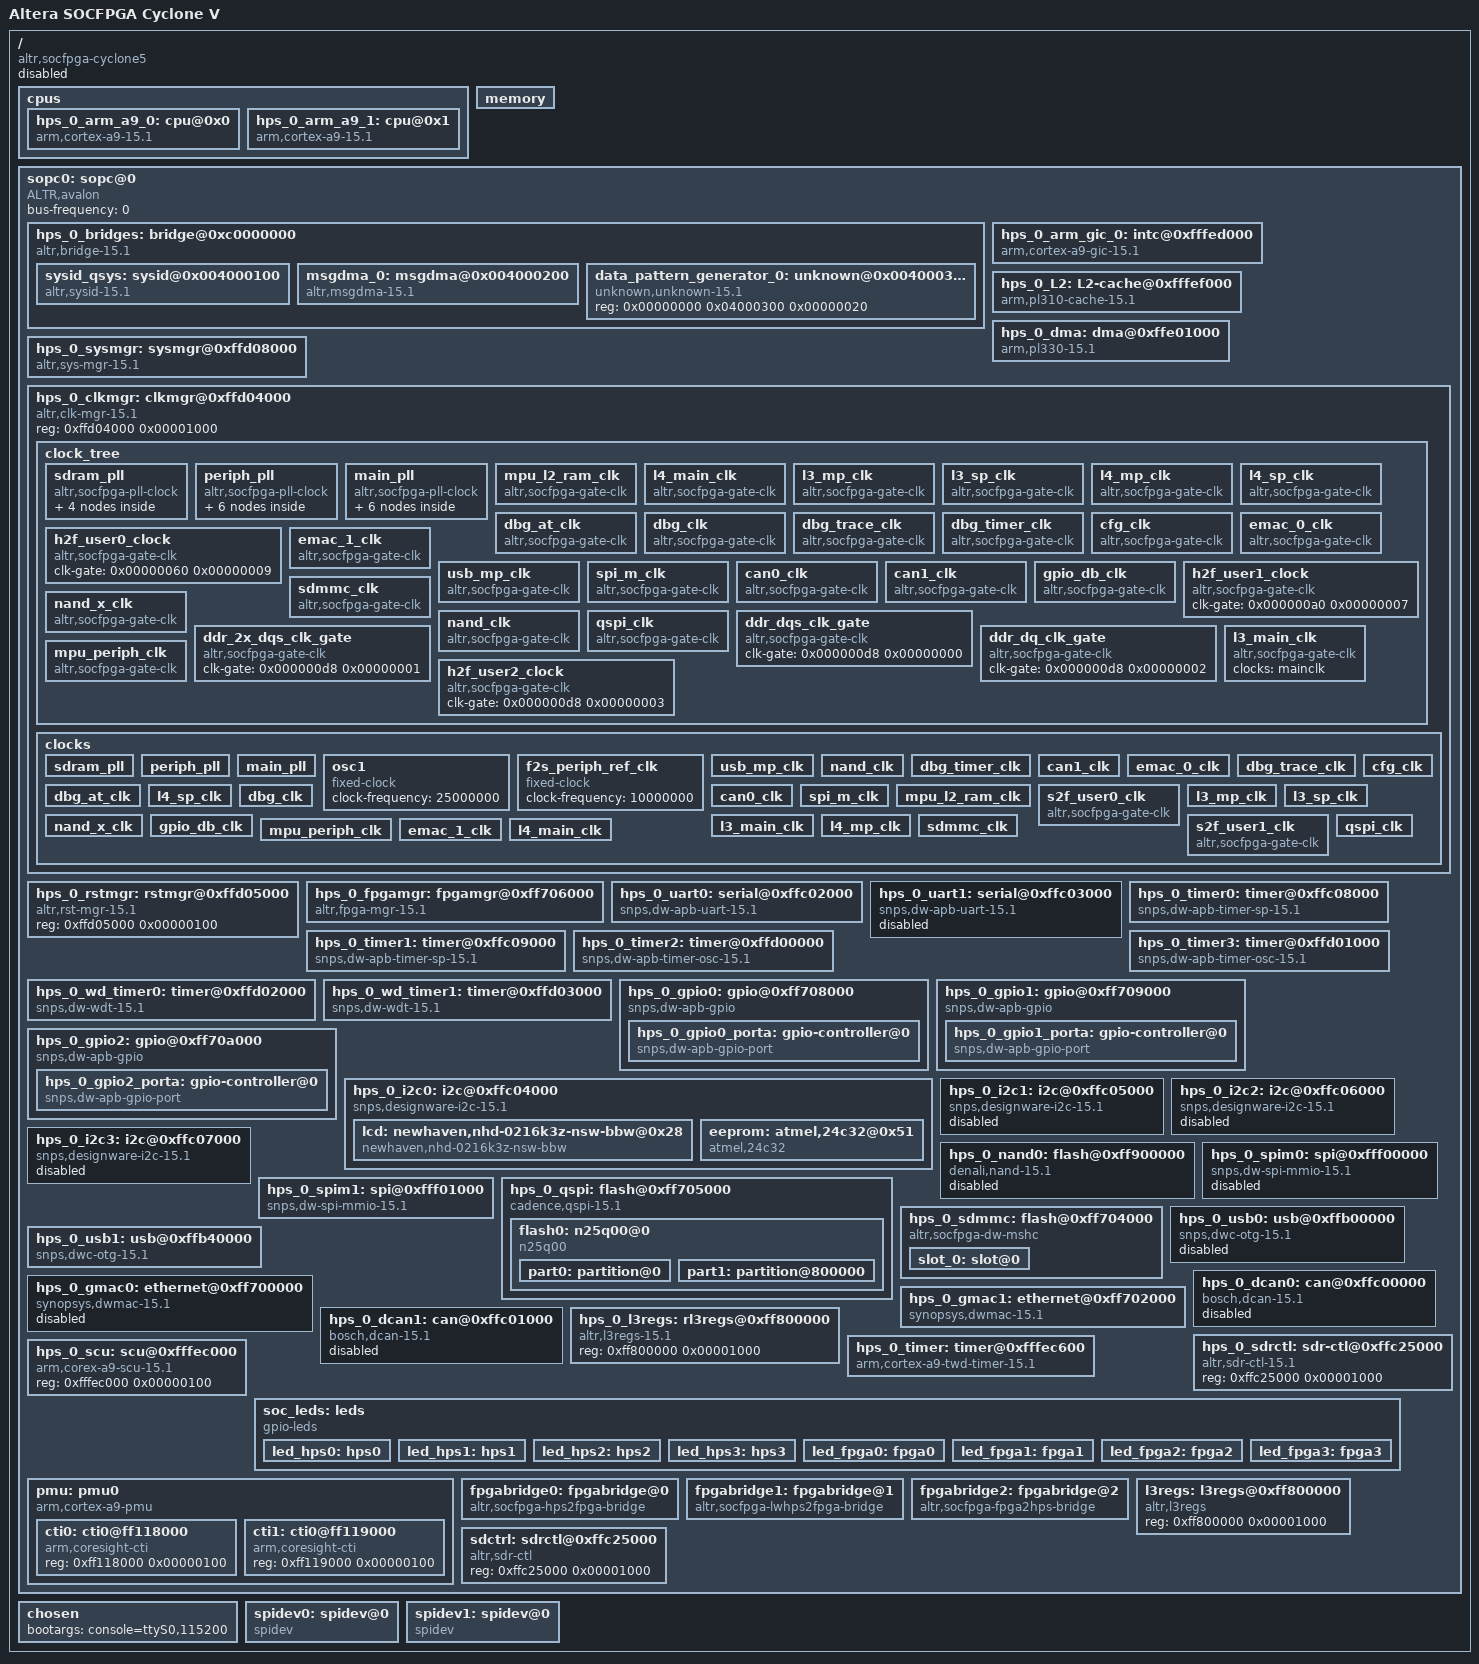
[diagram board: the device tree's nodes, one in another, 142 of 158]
/*
 * This devicetree is generated by sopc2dts version 15.1 [94267f754b718da09506aebbe5343be8fdba1582] on Mon Jul 25 16:30:17 CST 2016
 * Sopc2dts is written by Walter Goossens <waltergoossens@home.nl>
 * in cooperation with the nios2 community <nios2-dev@lists.rocketboards.org>
 */
/dts-v1/;

/ {
	model = "Altera SOCFPGA Cyclone V";	/* appended from boardinfo */
	compatible = "altr,socfpga-cyclone5", "altr,socfpga";	/* appended from boardinfo */
	#address-cells = <1>;
	#size-cells = <1>;
	status = "disabled";	/* appended from boardinfo */
	clocks = <&per_base_clk>;	/* appended from boardinfo */

	cpus {
		#address-cells = <1>;
		#size-cells = <0>;

		hps_0_arm_a9_0: cpu@0x0 {
			device_type = "cpu";
			compatible = "arm,cortex-a9-15.1", "arm,cortex-a9";
			reg = <0x00000000>;
			next-level-cache = <&hps_0_L2>;	/* appended from boardinfo */
		}; //end cpu@0x0 (hps_0_arm_a9_0)

		hps_0_arm_a9_1: cpu@0x1 {
			device_type = "cpu";
			compatible = "arm,cortex-a9-15.1", "arm,cortex-a9";
			reg = <0x00000001>;
			next-level-cache = <&hps_0_L2>;	/* appended from boardinfo */
		}; //end cpu@0x1 (hps_0_arm_a9_1)
	}; //end cpus

	memory {
		device_type = "memory";
		reg = <0xc0000000 0x04000000>,
			<0xffff0000 0x00010000>,
			<0x00000000 0x80000000>;
	}; //end memory

	sopc0: sopc@0 {
		device_type = "soc";
		ranges;
		#address-cells = <1>;
		#size-cells = <1>;
		compatible = "ALTR,avalon", "simple-bus";
		bus-frequency = <0>;

		hps_0_bridges: bridge@0xc0000000 {
			compatible = "altr,bridge-15.1", "simple-bus";
			reg = <0xc0000000 0x20000000>,
				<0xff200000 0x00200000>;
			reg-names = "axi_h2f", "axi_h2f_lw";
			#address-cells = <2>;
			#size-cells = <1>;
			ranges = <0x00000000 0x04000100 0xc4000100 0x00000008>,
				<0x00000000 0x04000200 0xc4000200 0x00000020>,
				<0x00000000 0x04000300 0xc4000300 0x00000020>,
				<0x00000000 0x04000240 0xc4000240 0x00000010>,
				<0x00000000 0x00000000 0xc0000000 0x04000000>;

			sysid_qsys: sysid@0x004000100 {
				compatible = "altr,sysid-15.1", "altr,sysid-1.0";
				reg = <0x00000000 0x04000100 0x00000008>;
				id = <2899645186>;	/* embeddedsw.dts.params.id type NUMBER */
				timestamp = <1469198027>;	/* embeddedsw.dts.params.timestamp type NUMBER */
			}; //end sysid@0x004000100 (sysid_qsys)

			msgdma_0: msgdma@0x004000200 {
				compatible = "altr,msgdma-15.1", "altr,msgdma-1.0";
				reg = <0x00000000 0x04000200 0x00000020>,
					<0x00000000 0x04000240 0x00000010>;
				reg-names = "csr", "descriptor_slave";
			}; //end msgdma@0x004000200 (msgdma_0)

			data_pattern_generator_0: unknown@0x004000300 {
				compatible = "unknown,unknown-15.1";
				reg = <0x00000000 0x04000300 0x00000020>;
			}; //end unknown@0x004000300 (data_pattern_generator_0)
		}; //end bridge@0xc0000000 (hps_0_bridges)

		hps_0_arm_gic_0: intc@0xfffed000 {
			compatible = "arm,cortex-a9-gic-15.1", "arm,cortex-a9-gic";
			reg = <0xfffed000 0x00001000>,
				<0xfffec100 0x00000100>;
			reg-names = "axi_slave0", "axi_slave1";
			interrupt-controller;
			#interrupt-cells = <3>;
		}; //end intc@0xfffed000 (hps_0_arm_gic_0)

		hps_0_L2: L2-cache@0xfffef000 {
			compatible = "arm,pl310-cache-15.1", "arm,pl310-cache";
			reg = <0xfffef000 0x00001000>;
			interrupt-parent = <&hps_0_arm_gic_0>;
			interrupts = <0 38 4>;
			cache-level = <2>;	/* embeddedsw.dts.params.cache-level type NUMBER */
			cache-unified;	/* appended from boardinfo */
			arm,tag-latency = <1 1 1>;	/* appended from boardinfo */
			arm,data-latency = <2 1 1>;	/* appended from boardinfo */
		}; //end L2-cache@0xfffef000 (hps_0_L2)

		hps_0_dma: dma@0xffe01000 {
			compatible = "arm,pl330-15.1", "arm,pl330", "arm,primecell";
			reg = <0xffe01000 0x00001000>;
			interrupt-parent = <&hps_0_arm_gic_0>;
			interrupts = <0 104 4>;
			#dma-cells = <1>;	/* embeddedsw.dts.params.#dma-cells type NUMBER */
			#dma-channels = <8>;	/* embeddedsw.dts.params.#dma-channels type NUMBER */
			#dma-requests = <32>;	/* embeddedsw.dts.params.#dma-requests type NUMBER */
			clock-names = "apb_pclk";	/* embeddedsw.dts.params.clock-names type STRING */
			copy-align = <3>;	/* embeddedsw.dts.params.copy-align type NUMBER */
			nr-irqs = <9>;	/* embeddedsw.dts.params.nr-irqs type NUMBER */
			nr-valid-peri = <9>;	/* embeddedsw.dts.params.nr-valid-peri type NUMBER */
		}; //end dma@0xffe01000 (hps_0_dma)

		hps_0_sysmgr: sysmgr@0xffd08000 {
			compatible = "altr,sys-mgr-15.1", "altr,sys-mgr", "syscon", "syscon";
			reg = <0xffd08000 0x00000400>;
			cpu1-start-addr = <0xffd080c4>;	/* appended from boardinfo */
		}; //end sysmgr@0xffd08000 (hps_0_sysmgr)

		hps_0_clkmgr: clkmgr@0xffd04000 {
			compatible = "altr,clk-mgr-15.1", "altr,clk-mgr";
			reg = <0xffd04000 0x00001000>;

			clock_tree {
				#size-cells = <0>;
				#address-cells = <1>;

				sdram_pll: sdram_pll {
					compatible = "altr,socfpga-pll-clock";	/* appended from boardinfo */
					reg = <0x000000c0>;	/* appended from boardinfo */
					#clock-cells = <0>;	/* appended from boardinfo */
					#address-cells = <1>;	/* appended from boardinfo */
					#size-cells = <0>;	/* appended from boardinfo */
					clocks = <&osc1>;	/* appended from boardinfo */

					ddr_dqs_clk: ddr_dqs_clk {
						compatible = "altr,socfpga-perip-clk";	/* appended from boardinfo */
						reg = <0x000000c8>;	/* appended from boardinfo */
						#clock-cells = <0>;	/* appended from boardinfo */
						clocks = <&sdram_pll>;	/* appended from boardinfo */
					}; //end ddr_dqs_clk (ddr_dqs_clk)

					ddr_2x_dqs_clk: ddr_2x_dqs_clk {
						compatible = "altr,socfpga-perip-clk";	/* appended from boardinfo */
						reg = <0x000000cc>;	/* appended from boardinfo */
						#clock-cells = <0>;	/* appended from boardinfo */
						clocks = <&sdram_pll>;	/* appended from boardinfo */
					}; //end ddr_2x_dqs_clk (ddr_2x_dqs_clk)

					ddr_dq_clk: ddr_dq_clk {
						compatible = "altr,socfpga-perip-clk";	/* appended from boardinfo */
						reg = <0x000000d0>;	/* appended from boardinfo */
						#clock-cells = <0>;	/* appended from boardinfo */
						clocks = <&sdram_pll>;	/* appended from boardinfo */
					}; //end ddr_dq_clk (ddr_dq_clk)

					s2f_usr2_clk: s2f_usr2_clk {
						compatible = "altr,socfpga-perip-clk";	/* appended from boardinfo */
						reg = <0x000000d4>;	/* appended from boardinfo */
						#clock-cells = <0>;	/* appended from boardinfo */
						clocks = <&sdram_pll>;	/* appended from boardinfo */
					}; //end s2f_usr2_clk (s2f_usr2_clk)

					ddr_dqs_clk: ddr_dqs_clk {
					}; //end ddr_dqs_clk (ddr_dqs_clk)

					ddr_2x_dqs_clk: ddr_2x_dqs_clk {
					}; //end ddr_2x_dqs_clk (ddr_2x_dqs_clk)

					ddr_dq_clk: ddr_dq_clk {
					}; //end ddr_dq_clk (ddr_dq_clk)

					s2f_usr2_clk: s2f_usr2_clk {
					}; //end s2f_usr2_clk (s2f_usr2_clk)
				}; //end sdram_pll (sdram_pll)

				periph_pll: periph_pll {
					compatible = "altr,socfpga-pll-clock";	/* appended from boardinfo */
					reg = <0x00000080>;	/* appended from boardinfo */
					#clock-cells = <0>;	/* appended from boardinfo */
					#address-cells = <1>;	/* appended from boardinfo */
					#size-cells = <0>;	/* appended from boardinfo */
					clocks = <&osc1>;	/* appended from boardinfo */

					per_nand_mmc_clk: per_nand_mmc_clk {
						compatible = "altr,socfpga-perip-clk";	/* appended from boardinfo */
						reg = <0x00000094>;	/* appended from boardinfo */
						#clock-cells = <0>;	/* appended from boardinfo */
						clocks = <&periph_pll>;	/* appended from boardinfo */
					}; //end per_nand_mmc_clk (per_nand_mmc_clk)

					per_base_clk: per_base_clk {
						compatible = "altr,socfpga-perip-clk";	/* appended from boardinfo */
						reg = <0x00000098>;	/* appended from boardinfo */
						#clock-cells = <0>;	/* appended from boardinfo */
						clocks = <&periph_pll>;	/* appended from boardinfo */
					}; //end per_base_clk (per_base_clk)

					per_qspi_clk: per_qspi_clk {
						compatible = "altr,socfpga-perip-clk";	/* appended from boardinfo */
						reg = <0x00000090>;	/* appended from boardinfo */
						#clock-cells = <0>;	/* appended from boardinfo */
						clocks = <&periph_pll>;	/* appended from boardinfo */
					}; //end per_qspi_clk (per_qspi_clk)

					s2f_usr1_clk: s2f_usr1_clk {
						compatible = "altr,socfpga-perip-clk";	/* appended from boardinfo */
						reg = <0x0000009c>;	/* appended from boardinfo */
						#clock-cells = <0>;	/* appended from boardinfo */
						clocks = <&periph_pll>;	/* appended from boardinfo */
					}; //end s2f_usr1_clk (s2f_usr1_clk)

					emac0_clk: emac0_clk {
						compatible = "altr,socfpga-perip-clk";	/* appended from boardinfo */
						reg = <0x00000088>;	/* appended from boardinfo */
						#clock-cells = <0>;	/* appended from boardinfo */
						clocks = <&periph_pll>;	/* appended from boardinfo */
					}; //end emac0_clk (emac0_clk)

					emac1_clk: emac1_clk {
						compatible = "altr,socfpga-perip-clk";	/* appended from boardinfo */
						reg = <0x0000008c>;	/* appended from boardinfo */
						#clock-cells = <0>;	/* appended from boardinfo */
						clocks = <&periph_pll>;	/* appended from boardinfo */
					}; //end emac1_clk (emac1_clk)

					per_nand_mmc_clk: per_nand_mmc_clk {
					}; //end per_nand_mmc_clk (per_nand_mmc_clk)

					per_base_clk: per_base_clk {
					}; //end per_base_clk (per_base_clk)

					per_qspi_clk: per_qspi_clk {
					}; //end per_qspi_clk (per_qspi_clk)

					s2f_usr1_clk: s2f_usr1_clk {
					}; //end s2f_usr1_clk (s2f_usr1_clk)

					emac0_clk: emac0_clk {
					}; //end emac0_clk (emac0_clk)

					emac1_clk: emac1_clk {
					}; //end emac1_clk (emac1_clk)
				}; //end periph_pll (periph_pll)

				main_pll: main_pll {
					compatible = "altr,socfpga-pll-clock";	/* appended from boardinfo */
					reg = <0x00000040>;	/* appended from boardinfo */
					#clock-cells = <0>;	/* appended from boardinfo */
					#address-cells = <1>;	/* appended from boardinfo */
					#size-cells = <0>;	/* appended from boardinfo */
					clocks = <&osc1>;	/* appended from boardinfo */

					cfg_s2f_usr0_clk: cfg_s2f_usr0_clk {
						compatible = "altr,socfpga-perip-clk";	/* appended from boardinfo */
						reg = <0x0000005c>;	/* appended from boardinfo */
						#clock-cells = <0>;	/* appended from boardinfo */
						clocks = <&main_pll>;	/* appended from boardinfo */
					}; //end cfg_s2f_usr0_clk (cfg_s2f_usr0_clk)

					main_qspi_clk: main_qspi_clk {
						compatible = "altr,socfpga-perip-clk";	/* appended from boardinfo */
						reg = <0x00000054>;	/* appended from boardinfo */
						#clock-cells = <0>;	/* appended from boardinfo */
						clocks = <&main_pll>;	/* appended from boardinfo */
					}; //end main_qspi_clk (main_qspi_clk)

					dbg_base_clk: dbg_base_clk {
						compatible = "altr,socfpga-perip-clk";	/* appended from boardinfo */
						reg = <0x00000050>;	/* appended from boardinfo */
						#clock-cells = <0>;	/* appended from boardinfo */
						div-reg = <0x000000e8 0x00000000 0x00000009>;
						clocks = <&main_pll>;	/* appended from boardinfo */
						fixed-divider = <4>;	/* appended from boardinfo */
					}; //end dbg_base_clk (dbg_base_clk)

					mpuclk: mpuclk {
						compatible = "altr,socfpga-perip-clk";	/* appended from boardinfo */
						reg = <0x00000048>;	/* appended from boardinfo */
						#clock-cells = <0>;	/* appended from boardinfo */
						div-reg = <0x000000e0 0x00000000 0x00000009>;
						clocks = <&main_pll>;	/* appended from boardinfo */
						fixed-divider = <2>;	/* appended from boardinfo */
					}; //end mpuclk (mpuclk)

					mainclk: mainclk {
						compatible = "altr,socfpga-perip-clk";	/* appended from boardinfo */
						reg = <0x0000004c>;	/* appended from boardinfo */
						#clock-cells = <0>;	/* appended from boardinfo */
						div-reg = <0x000000e4 0x00000000 0x00000009>;
						clocks = <&main_pll>;	/* appended from boardinfo */
						fixed-divider = <4>;	/* appended from boardinfo */
					}; //end mainclk (mainclk)

					main_nand_sdmmc_clk: main_nand_sdmmc_clk {
						compatible = "altr,socfpga-perip-clk";	/* appended from boardinfo */
						reg = <0x00000058>;	/* appended from boardinfo */
						#clock-cells = <0>;	/* appended from boardinfo */
						clocks = <&main_pll>;	/* appended from boardinfo */
					}; //end main_nand_sdmmc_clk (main_nand_sdmmc_clk)

					cfg_s2f_usr0_clk: cfg_s2f_usr0_clk {
					}; //end cfg_s2f_usr0_clk (cfg_s2f_usr0_clk)

					main_qspi_clk: main_qspi_clk {
					}; //end main_qspi_clk (main_qspi_clk)

					dbg_base_clk: dbg_base_clk {
					}; //end dbg_base_clk (dbg_base_clk)

					mpuclk: mpuclk {
					}; //end mpuclk (mpuclk)

					mainclk: mainclk {
					}; //end mainclk (mainclk)

					main_nand_sdmmc_clk: main_nand_sdmmc_clk {
					}; //end main_nand_sdmmc_clk (main_nand_sdmmc_clk)
				}; //end main_pll (main_pll)

				mpu_l2_ram_clk: mpu_l2_ram_clk {
					compatible = "altr,socfpga-gate-clk";	/* appended from boardinfo */
					#clock-cells = <0>;	/* appended from boardinfo */
					fixed-divider = <2>;	/* appended from boardinfo */
					clocks = <&mpuclk>;	/* appended from boardinfo */
				}; //end mpu_l2_ram_clk (mpu_l2_ram_clk)

				l4_main_clk: l4_main_clk {
					compatible = "altr,socfpga-gate-clk";	/* appended from boardinfo */
					#clock-cells = <0>;	/* appended from boardinfo */
					clk-gate = <0x00000060 0>;	/* appended from boardinfo */
					clocks = <&mainclk>;	/* appended from boardinfo */
				}; //end l4_main_clk (l4_main_clk)

				l3_mp_clk: l3_mp_clk {
					compatible = "altr,socfpga-gate-clk";	/* appended from boardinfo */
					#clock-cells = <0>;	/* appended from boardinfo */
					clk-gate = <0x00000060 1>;	/* appended from boardinfo */
					div-reg = <0x00000064 0 2>;	/* appended from boardinfo */
					clocks = <&mainclk>;	/* appended from boardinfo */
				}; //end l3_mp_clk (l3_mp_clk)

				l3_sp_clk: l3_sp_clk {
					compatible = "altr,socfpga-gate-clk";	/* appended from boardinfo */
					#clock-cells = <0>;	/* appended from boardinfo */
					div-reg = <0x00000064 2 2>;	/* appended from boardinfo */
					clocks = <&mainclk>;	/* appended from boardinfo */
				}; //end l3_sp_clk (l3_sp_clk)

				l4_mp_clk: l4_mp_clk {
					compatible = "altr,socfpga-gate-clk";	/* appended from boardinfo */
					#clock-cells = <0>;	/* appended from boardinfo */
					clk-gate = <0x00000060 2>;	/* appended from boardinfo */
					div-reg = <0x00000064 4 3>;	/* appended from boardinfo */
					clocks = <&mainclk>;	/* appended from boardinfo */
				}; //end l4_mp_clk (l4_mp_clk)

				l4_sp_clk: l4_sp_clk {
					compatible = "altr,socfpga-gate-clk";	/* appended from boardinfo */
					#clock-cells = <0>;	/* appended from boardinfo */
					clk-gate = <0x00000060 3>;	/* appended from boardinfo */
					div-reg = <0x00000064 7 3>;	/* appended from boardinfo */
					clocks = <&mainclk &per_base_clk>;	/* appended from boardinfo */
				}; //end l4_sp_clk (l4_sp_clk)

				dbg_at_clk: dbg_at_clk {
					compatible = "altr,socfpga-gate-clk";	/* appended from boardinfo */
					#clock-cells = <0>;	/* appended from boardinfo */
					clk-gate = <0x00000060 4>;	/* appended from boardinfo */
					div-reg = <0x00000068 0 2>;	/* appended from boardinfo */
					clocks = <&dbg_base_clk>;	/* appended from boardinfo */
				}; //end dbg_at_clk (dbg_at_clk)

				dbg_clk: dbg_clk {
					compatible = "altr,socfpga-gate-clk";	/* appended from boardinfo */
					#clock-cells = <0>;	/* appended from boardinfo */
					clk-gate = <0x00000060 5>;	/* appended from boardinfo */
					div-reg = <0x00000068 2 2>;	/* appended from boardinfo */
					clocks = <&dbg_base_clk>;	/* appended from boardinfo */
				}; //end dbg_clk (dbg_clk)

				dbg_trace_clk: dbg_trace_clk {
					compatible = "altr,socfpga-gate-clk";	/* appended from boardinfo */
					#clock-cells = <0>;	/* appended from boardinfo */
					clk-gate = <0x00000060 6>;	/* appended from boardinfo */
					div-reg = <0x0000006c 0 3>;	/* appended from boardinfo */
					clocks = <&dbg_base_clk>;	/* appended from boardinfo */
				}; //end dbg_trace_clk (dbg_trace_clk)

				dbg_timer_clk: dbg_timer_clk {
					compatible = "altr,socfpga-gate-clk";	/* appended from boardinfo */
					#clock-cells = <0>;	/* appended from boardinfo */
					clk-gate = <0x00000060 7>;	/* appended from boardinfo */
					clocks = <&dbg_base_clk>;	/* appended from boardinfo */
				}; //end dbg_timer_clk (dbg_timer_clk)

				cfg_clk: cfg_clk {
					compatible = "altr,socfpga-gate-clk";	/* appended from boardinfo */
					#clock-cells = <0>;	/* appended from boardinfo */
					clk-gate = <0x00000060 8>;	/* appended from boardinfo */
					clocks = <&cfg_s2f_usr0_clk>;	/* appended from boardinfo */
				}; //end cfg_clk (cfg_clk)

				h2f_user0_clock: h2f_user0_clock {
					compatible = "altr,socfpga-gate-clk";
					#clock-cells = <0>;
					clk-gate = <0x00000060 0x00000009>;
				}; //end h2f_user0_clock (h2f_user0_clock)

				emac_0_clk: emac_0_clk {
					compatible = "altr,socfpga-gate-clk";	/* appended from boardinfo */
					#clock-cells = <0>;	/* appended from boardinfo */
					clk-gate = <0x000000a0 0>;	/* appended from boardinfo */
					clocks = <&emac0_clk>;	/* appended from boardinfo */
				}; //end emac_0_clk (emac_0_clk)

				emac_1_clk: emac_1_clk {
					compatible = "altr,socfpga-gate-clk";	/* appended from boardinfo */
					#clock-cells = <0>;	/* appended from boardinfo */
					clk-gate = <0x000000a0 1>;	/* appended from boardinfo */
					clocks = <&emac1_clk>;	/* appended from boardinfo */
				}; //end emac_1_clk (emac_1_clk)

				usb_mp_clk: usb_mp_clk {
					compatible = "altr,socfpga-gate-clk";	/* appended from boardinfo */
					#clock-cells = <0>;	/* appended from boardinfo */
					clk-gate = <0x000000a0 2>;	/* appended from boardinfo */
					div-reg = <0x000000a4 0 3>;	/* appended from boardinfo */
					clocks = <&per_base_clk>;	/* appended from boardinfo */
				}; //end usb_mp_clk (usb_mp_clk)

				spi_m_clk: spi_m_clk {
					compatible = "altr,socfpga-gate-clk";	/* appended from boardinfo */
					#clock-cells = <0>;	/* appended from boardinfo */
					clk-gate = <0x000000a0 3>;	/* appended from boardinfo */
					div-reg = <0x000000a4 3 3>;	/* appended from boardinfo */
					clocks = <&per_base_clk>;	/* appended from boardinfo */
				}; //end spi_m_clk (spi_m_clk)

				can0_clk: can0_clk {
					compatible = "altr,socfpga-gate-clk";	/* appended from boardinfo */
					#clock-cells = <0>;	/* appended from boardinfo */
					clk-gate = <0x000000a0 4>;	/* appended from boardinfo */
					div-reg = <0x000000a4 6 3>;	/* appended from boardinfo */
					clocks = <&per_base_clk>;	/* appended from boardinfo */
				}; //end can0_clk (can0_clk)

				can1_clk: can1_clk {
					compatible = "altr,socfpga-gate-clk";	/* appended from boardinfo */
					#clock-cells = <0>;	/* appended from boardinfo */
					clk-gate = <0x000000a0 5>;	/* appended from boardinfo */
					div-reg = <0x000000a4 9 3>;	/* appended from boardinfo */
					clocks = <&per_base_clk>;	/* appended from boardinfo */
				}; //end can1_clk (can1_clk)

				gpio_db_clk: gpio_db_clk {
					compatible = "altr,socfpga-gate-clk";	/* appended from boardinfo */
					#clock-cells = <0>;	/* appended from boardinfo */
					clk-gate = <0x000000a0 6>;	/* appended from boardinfo */
					div-reg = <0x000000a8 0 24>;	/* appended from boardinfo */
					clocks = <&per_base_clk>;	/* appended from boardinfo */
				}; //end gpio_db_clk (gpio_db_clk)

				h2f_user1_clock: h2f_user1_clock {
					compatible = "altr,socfpga-gate-clk";
					#clock-cells = <0>;
					clk-gate = <0x000000a0 0x00000007>;
				}; //end h2f_user1_clock (h2f_user1_clock)

				sdmmc_clk: sdmmc_clk {
					compatible = "altr,socfpga-gate-clk";	/* appended from boardinfo */
					#clock-cells = <0>;	/* appended from boardinfo */
					clk-gate = <0x000000a0 8>;	/* appended from boardinfo */
					clocks = <&f2s_periph_ref_clk &main_nand_sdmmc_clk &per_nand_mmc_clk>;	/* appended from boardinfo */
				}; //end sdmmc_clk (sdmmc_clk)

				nand_x_clk: nand_x_clk {
					compatible = "altr,socfpga-gate-clk";	/* appended from boardinfo */
					#clock-cells = <0>;	/* appended from boardinfo */
					clk-gate = <0x000000a0 9>;	/* appended from boardinfo */
					clocks = <&f2s_periph_ref_clk &main_nand_sdmmc_clk &per_nand_mmc_clk>;	/* appended from boardinfo */
				}; //end nand_x_clk (nand_x_clk)

				nand_clk: nand_clk {
					compatible = "altr,socfpga-gate-clk";	/* appended from boardinfo */
					#clock-cells = <0>;	/* appended from boardinfo */
					clk-gate = <0x000000a0 10>;	/* appended from boardinfo */
					fixed-divider = <4>;	/* appended from boardinfo */
					clocks = <&f2s_periph_ref_clk &main_nand_sdmmc_clk &per_nand_mmc_clk>;	/* appended from boardinfo */
				}; //end nand_clk (nand_clk)

				qspi_clk: qspi_clk {
					compatible = "altr,socfpga-gate-clk";	/* appended from boardinfo */
					#clock-cells = <0>;	/* appended from boardinfo */
					clk-gate = <0x000000a0 11>;	/* appended from boardinfo */
					clocks = <&f2s_periph_ref_clk &main_qspi_clk &per_qspi_clk>;	/* appended from boardinfo */
				}; //end qspi_clk (qspi_clk)

				ddr_dqs_clk_gate: ddr_dqs_clk_gate {
					compatible = "altr,socfpga-gate-clk";
					#clock-cells = <0>;
					clk-gate = <0x000000d8 0x00000000>;
				}; //end ddr_dqs_clk_gate (ddr_dqs_clk_gate)

				ddr_2x_dqs_clk_gate: ddr_2x_dqs_clk_gate {
					compatible = "altr,socfpga-gate-clk";
					#clock-cells = <0>;
					clk-gate = <0x000000d8 0x00000001>;
				}; //end ddr_2x_dqs_clk_gate (ddr_2x_dqs_clk_gate)

				ddr_dq_clk_gate: ddr_dq_clk_gate {
					compatible = "altr,socfpga-gate-clk";
					#clock-cells = <0>;
					clk-gate = <0x000000d8 0x00000002>;
				}; //end ddr_dq_clk_gate (ddr_dq_clk_gate)

				h2f_user2_clock: h2f_user2_clock {
					compatible = "altr,socfpga-gate-clk";
					#clock-cells = <0>;
					clk-gate = <0x000000d8 0x00000003>;
				}; //end h2f_user2_clock (h2f_user2_clock)

				l3_main_clk: l3_main_clk {
					compatible = "altr,socfpga-gate-clk";	/* appended from boardinfo */
					#clock-cells = <0>;	/* appended from boardinfo */
					clocks = <&mainclk>;	/* appended from boardinfo */
				}; //end l3_main_clk (l3_main_clk)

				mpu_periph_clk: mpu_periph_clk {
					compatible = "altr,socfpga-gate-clk";	/* appended from boardinfo */
					#clock-cells = <0>;	/* appended from boardinfo */
					reg = <0x00000000>;
					fixed-divider = <4>;	/* appended from boardinfo */
					clocks = <&mpuclk>;	/* appended from boardinfo */
				}; //end mpu_periph_clk (mpu_periph_clk)
			}; //end clock_tree

			clocks: clocks {
				#size-cells = <0>;	/* appended from boardinfo */
				#address-cells = <1>;	/* appended from boardinfo */

				sdram_pll: sdram_pll {
				}; //end sdram_pll (sdram_pll)

				periph_pll: periph_pll {
				}; //end periph_pll (periph_pll)

				main_pll: main_pll {
				}; //end main_pll (main_pll)

				osc1: osc1 {
					#clock-cells = <0>;	/* appended from boardinfo */
					compatible = "fixed-clock";	/* appended from boardinfo */
					clock-frequency = <25000000>;	/* appended from boardinfo */
				}; //end osc1 (osc1)

				f2s_periph_ref_clk: f2s_periph_ref_clk {
					#clock-cells = <0>;	/* appended from boardinfo */
					compatible = "fixed-clock";	/* appended from boardinfo */
					clock-frequency = <10000000>;	/* appended from boardinfo */
				}; //end f2s_periph_ref_clk (f2s_periph_ref_clk)

				usb_mp_clk: usb_mp_clk {
				}; //end usb_mp_clk (usb_mp_clk)

				nand_clk: nand_clk {
				}; //end nand_clk (nand_clk)

				dbg_timer_clk: dbg_timer_clk {
				}; //end dbg_timer_clk (dbg_timer_clk)

				can1_clk: can1_clk {
				}; //end can1_clk (can1_clk)

				emac_0_clk: emac_0_clk {
				}; //end emac_0_clk (emac_0_clk)

				dbg_trace_clk: dbg_trace_clk {
				}; //end dbg_trace_clk (dbg_trace_clk)

				dbg_at_clk: dbg_at_clk {
				}; //end dbg_at_clk (dbg_at_clk)

				l4_sp_clk: l4_sp_clk {
				}; //end l4_sp_clk (l4_sp_clk)

				can0_clk: can0_clk {
				}; //end can0_clk (can0_clk)

				spi_m_clk: spi_m_clk {
				}; //end spi_m_clk (spi_m_clk)

				cfg_clk: cfg_clk {
				}; //end cfg_clk (cfg_clk)

				mpu_l2_ram_clk: mpu_l2_ram_clk {
				}; //end mpu_l2_ram_clk (mpu_l2_ram_clk)

				s2f_user0_clk: s2f_user0_clk {
					#clock-cells = <0>;	/* appended from boardinfo */
					compatible = "altr,socfpga-gate-clk";	/* appended from boardinfo */
					clocks = <&cfg_s2f_usr0_clk>;	/* appended from boardinfo */
					clk-gate = <0x00000060 9>;	/* appended from boardinfo */
				}; //end s2f_user0_clk (s2f_user0_clk)

				l3_mp_clk: l3_mp_clk {
				}; //end l3_mp_clk (l3_mp_clk)

				dbg_clk: dbg_clk {
				}; //end dbg_clk (dbg_clk)

				l3_sp_clk: l3_sp_clk {
				}; //end l3_sp_clk (l3_sp_clk)

				nand_x_clk: nand_x_clk {
				}; //end nand_x_clk (nand_x_clk)

				gpio_db_clk: gpio_db_clk {
				}; //end gpio_db_clk (gpio_db_clk)

				l3_main_clk: l3_main_clk {
				}; //end l3_main_clk (l3_main_clk)

				l4_mp_clk: l4_mp_clk {
				}; //end l4_mp_clk (l4_mp_clk)

				s2f_user1_clk: s2f_user1_clk {
					#clock-cells = <0>;	/* appended from boardinfo */
					compatible = "altr,socfpga-gate-clk";	/* appended from boardinfo */
					clocks = <&s2f_usr1_clk>;	/* appended from boardinfo */
					clk-gate = <0x000000a0 7>;	/* appended from boardinfo */
				}; //end s2f_user1_clk (s2f_user1_clk)

				mpu_periph_clk: mpu_periph_clk {
				}; //end mpu_periph_clk (mpu_periph_clk)

				sdmmc_clk: sdmmc_clk {
				}; //end sdmmc_clk (sdmmc_clk)

				qspi_clk: qspi_clk {
				}; //end qspi_clk (qspi_clk)

				emac_1_clk: emac_1_clk {
				}; //end emac_1_clk (emac_1_clk)

				l4_main_clk: l4_main_clk {
				}; //end l4_main_clk (l4_main_clk)
			}; //end clocks (clocks)
		}; //end clkmgr@0xffd04000 (hps_0_clkmgr)

		hps_0_rstmgr: rstmgr@0xffd05000 {
			compatible = "altr,rst-mgr-15.1", "altr,rst-mgr", "syscon", "syscon";
			reg = <0xffd05000 0x00000100>;
		}; //end rstmgr@0xffd05000 (hps_0_rstmgr)

		hps_0_fpgamgr: fpgamgr@0xff706000 {
			compatible = "altr,fpga-mgr-15.1", "altr,fpga-mgr";
			reg = <0xff706000 0x00001000>,
				<0xffb90000 0x00000100>;
			reg-names = "axi_slave0", "axi_slave1";
			interrupt-parent = <&hps_0_arm_gic_0>;
			interrupts = <0 175 4>;
			transport = "mmio";	/* embeddedsw.dts.params.transport type STRING */
		}; //end fpgamgr@0xff706000 (hps_0_fpgamgr)

		hps_0_uart0: serial@0xffc02000 {
			compatible = "snps,dw-apb-uart-15.1", "snps,dw-apb-uart";
			reg = <0xffc02000 0x00000100>;
			interrupt-parent = <&hps_0_arm_gic_0>;
			interrupts = <0 162 4>;
			reg-io-width = <4>;	/* embeddedsw.dts.params.reg-io-width type NUMBER */
			reg-shift = <2>;	/* embeddedsw.dts.params.reg-shift type NUMBER */
			status = "okay";	/* embeddedsw.dts.params.status type STRING */
			clock-frequency = <100000000>;	/* appended from boardinfo */
		}; //end serial@0xffc02000 (hps_0_uart0)

		hps_0_uart1: serial@0xffc03000 {
			compatible = "snps,dw-apb-uart-15.1", "snps,dw-apb-uart";
			reg = <0xffc03000 0x00000100>;
			interrupt-parent = <&hps_0_arm_gic_0>;
			interrupts = <0 163 4>;
			reg-io-width = <4>;	/* embeddedsw.dts.params.reg-io-width type NUMBER */
			reg-shift = <2>;	/* embeddedsw.dts.params.reg-shift type NUMBER */
			status = "disabled";	/* appended from boardinfo */
			clock-frequency = <100000000>;	/* appended from boardinfo */
		}; //end serial@0xffc03000 (hps_0_uart1)

		hps_0_timer0: timer@0xffc08000 {
			compatible = "snps,dw-apb-timer-sp-15.1", "snps,dw-apb-timer-sp";
			reg = <0xffc08000 0x00000100>;
			interrupt-parent = <&hps_0_arm_gic_0>;
			interrupts = <0 167 4>;
			clock-names = "timer";	/* embeddedsw.dts.params.clock-names type STRING */
			clock-frequency = <100000000>;	/* appended from boardinfo */
		}; //end timer@0xffc08000 (hps_0_timer0)

		hps_0_timer1: timer@0xffc09000 {
			compatible = "snps,dw-apb-timer-sp-15.1", "snps,dw-apb-timer-sp";
			reg = <0xffc09000 0x00000100>;
			interrupt-parent = <&hps_0_arm_gic_0>;
			interrupts = <0 168 4>;
			clock-names = "timer";	/* embeddedsw.dts.params.clock-names type STRING */
			clock-frequency = <100000000>;	/* appended from boardinfo */
		}; //end timer@0xffc09000 (hps_0_timer1)

		hps_0_timer2: timer@0xffd00000 {
			compatible = "snps,dw-apb-timer-osc-15.1", "snps,dw-apb-timer-osc";
			reg = <0xffd00000 0x00000100>;
			interrupt-parent = <&hps_0_arm_gic_0>;
			interrupts = <0 169 4>;
			clock-names = "timer";	/* embeddedsw.dts.params.clock-names type STRING */
			clock-frequency = <25000000>;	/* appended from boardinfo */
		}; //end timer@0xffd00000 (hps_0_timer2)

		hps_0_timer3: timer@0xffd01000 {
			compatible = "snps,dw-apb-timer-osc-15.1", "snps,dw-apb-timer-osc";
			reg = <0xffd01000 0x00000100>;
			interrupt-parent = <&hps_0_arm_gic_0>;
			interrupts = <0 170 4>;
			clock-names = "timer";	/* embeddedsw.dts.params.clock-names type STRING */
			clock-frequency = <25000000>;	/* appended from boardinfo */
		}; //end timer@0xffd01000 (hps_0_timer3)

		hps_0_wd_timer0: timer@0xffd02000 {
			compatible = "snps,dw-wdt-15.1", "snps,dw-wdt";
			reg = <0xffd02000 0x00000100>;
			interrupt-parent = <&hps_0_arm_gic_0>;
			interrupts = <0 171 4>;
			clock-names = "timer";	/* embeddedsw.dts.params.clock-names type STRING */
		}; //end timer@0xffd02000 (hps_0_wd_timer0)

		hps_0_wd_timer1: timer@0xffd03000 {
			compatible = "snps,dw-wdt-15.1", "snps,dw-wdt";
			reg = <0xffd03000 0x00000100>;
			interrupt-parent = <&hps_0_arm_gic_0>;
			interrupts = <0 172 4>;
			clock-names = "timer";	/* embeddedsw.dts.params.clock-names type STRING */
		}; //end timer@0xffd03000 (hps_0_wd_timer1)

		hps_0_gpio0: gpio@0xff708000 {
			compatible = "snps,dw-apb-gpio", "snps,dw-gpio-15.1", "snps,dw-gpio";
			reg = <0xff708000 0x00000100>;
			interrupt-parent = <&hps_0_arm_gic_0>;
			interrupts = <0 164 4>;
			#gpio-cells = <2>;
			gpio-controller;
			#address-cells = <1>;
			#size-cells = <0>;
			interrupt-controller;	/* appended from boardinfo */
			#interrupt-cells = <2>;	/* appended from boardinfo */
			clocks = <&per_base_clk>;	/* appended from boardinfo */

			hps_0_gpio0_porta: gpio-controller@0 {
				compatible = "snps,dw-apb-gpio-port";
				gpio-controller;
				#gpio-cells = <2>;
				snps,nr-gpios = <29>;
				reg = <0>;
				interrupt-controller;
				#interrupt-cells = <2>;
				interrupts = <0 164 4>;
				interrupt-parent = <&hps_0_arm_gic_0>;
			}; //end gpio-controller@0 (hps_0_gpio0_porta)
		}; //end gpio@0xff708000 (hps_0_gpio0)

		hps_0_gpio1: gpio@0xff709000 {
			compatible = "snps,dw-apb-gpio", "snps,dw-gpio-15.1", "snps,dw-gpio";
			reg = <0xff709000 0x00000100>;
			interrupt-parent = <&hps_0_arm_gic_0>;
			interrupts = <0 165 4>;
			#gpio-cells = <2>;
			gpio-controller;
			#address-cells = <1>;
			#size-cells = <0>;
			interrupt-controller;	/* appended from boardinfo */
			#interrupt-cells = <2>;	/* appended from boardinfo */
			clocks = <&per_base_clk>;	/* appended from boardinfo */

			hps_0_gpio1_porta: gpio-controller@0 {
				compatible = "snps,dw-apb-gpio-port";
				gpio-controller;
				#gpio-cells = <2>;
				snps,nr-gpios = <29>;
				reg = <0>;
				interrupt-controller;
				#interrupt-cells = <2>;
				interrupts = <0 165 4>;
				interrupt-parent = <&hps_0_arm_gic_0>;
			}; //end gpio-controller@0 (hps_0_gpio1_porta)
		}; //end gpio@0xff709000 (hps_0_gpio1)

		hps_0_gpio2: gpio@0xff70a000 {
			compatible = "snps,dw-apb-gpio", "snps,dw-gpio-15.1", "snps,dw-gpio";
			reg = <0xff70a000 0x00000100>;
			interrupt-parent = <&hps_0_arm_gic_0>;
			interrupts = <0 166 4>;
			#gpio-cells = <2>;
			gpio-controller;
			#address-cells = <1>;
			#size-cells = <0>;
			interrupt-controller;	/* appended from boardinfo */
			#interrupt-cells = <2>;	/* appended from boardinfo */
			clocks = <&per_base_clk>;	/* appended from boardinfo */

			hps_0_gpio2_porta: gpio-controller@0 {
				compatible = "snps,dw-apb-gpio-port";
				gpio-controller;
				#gpio-cells = <2>;
				snps,nr-gpios = <27>;
				reg = <0>;
				interrupt-controller;
				#interrupt-cells = <2>;
				interrupts = <0 166 4>;
				interrupt-parent = <&hps_0_arm_gic_0>;
			}; //end gpio-controller@0 (hps_0_gpio2_porta)
		}; //end gpio@0xff70a000 (hps_0_gpio2)

		hps_0_i2c0: i2c@0xffc04000 {
			compatible = "snps,designware-i2c-15.1", "snps,designware-i2c";
			reg = <0xffc04000 0x00000100>;
			interrupt-parent = <&hps_0_arm_gic_0>;
			interrupts = <0 158 4>;
			emptyfifo_hold_master = <1>;	/* embeddedsw.dts.params.emptyfifo_hold_master type NUMBER */
			status = "okay";	/* embeddedsw.dts.params.status type STRING */
			#address-cells = <1>;
			#size-cells = <0>;
			speed-mode = <0>;	/* appended from boardinfo */
			clocks = <&per_base_clk>;	/* appended from boardinfo */

			lcd: newhaven,nhd-0216k3z-nsw-bbw@0x28 {
				compatible = "newhaven,nhd-0216k3z-nsw-bbw";
				reg = <0x00000028>;
				height = <2>;	/* appended from boardinfo */
				width = <16>;	/* appended from boardinfo */
				brightness = <8>;	/* appended from boardinfo */
			}; //end newhaven,nhd-0216k3z-nsw-bbw@0x28 (lcd)

			eeprom: atmel,24c32@0x51 {
				compatible = "atmel,24c32";
				reg = <0x00000051>;
				pagesize = <32>;	/* appended from boardinfo */
			}; //end atmel,24c32@0x51 (eeprom)
		}; //end i2c@0xffc04000 (hps_0_i2c0)

		hps_0_i2c1: i2c@0xffc05000 {
			compatible = "snps,designware-i2c-15.1", "snps,designware-i2c";
			reg = <0xffc05000 0x00000100>;
			interrupt-parent = <&hps_0_arm_gic_0>;
			interrupts = <0 159 4>;
			emptyfifo_hold_master = <1>;	/* embeddedsw.dts.params.emptyfifo_hold_master type NUMBER */
			status = "disabled";	/* appended from boardinfo */
			clocks = <&per_base_clk>;	/* appended from boardinfo */
		}; //end i2c@0xffc05000 (hps_0_i2c1)

		hps_0_i2c2: i2c@0xffc06000 {
			compatible = "snps,designware-i2c-15.1", "snps,designware-i2c";
			reg = <0xffc06000 0x00000100>;
			interrupt-parent = <&hps_0_arm_gic_0>;
			interrupts = <0 160 4>;
			emptyfifo_hold_master = <1>;	/* embeddedsw.dts.params.emptyfifo_hold_master type NUMBER */
			status = "disabled";	/* appended from boardinfo */
			clocks = <&per_base_clk>;	/* appended from boardinfo */
		}; //end i2c@0xffc06000 (hps_0_i2c2)

		hps_0_i2c3: i2c@0xffc07000 {
			compatible = "snps,designware-i2c-15.1", "snps,designware-i2c";
			reg = <0xffc07000 0x00000100>;
			interrupt-parent = <&hps_0_arm_gic_0>;
			interrupts = <0 161 4>;
			emptyfifo_hold_master = <1>;	/* embeddedsw.dts.params.emptyfifo_hold_master type NUMBER */
			status = "disabled";	/* appended from boardinfo */
			clocks = <&per_base_clk>;	/* appended from boardinfo */
		}; //end i2c@0xffc07000 (hps_0_i2c3)

		hps_0_nand0: flash@0xff900000 {
			compatible = "denali,nand-15.1", "denali,denali-nand-dt";
			reg = <0xff900000 0x00010000>,
				<0xffb80000 0x00010000>;
			reg-names = "nand_data", "denali_reg";	/* embeddedsw.dts.params.reg-names type STRING */
			interrupt-parent = <&hps_0_arm_gic_0>;
			interrupts = <0 144 4>;
			#address-cells = <1>;	/* embeddedsw.dts.params.#address-cells type NUMBER */
			#size-cells = <1>;	/* embeddedsw.dts.params.#size-cells type NUMBER */
			status = "disabled";	/* appended from boardinfo */
			bank-width = <2>;
			device-width = <1>;
			clocks = <&nand_clk>;	/* appended from boardinfo */
		}; //end flash@0xff900000 (hps_0_nand0)

		hps_0_spim0: spi@0xfff00000 {
			compatible = "snps,dw-spi-mmio-15.1", "snps,dw-spi-mmio", "snps,dw-apb-ssi";
			reg = <0xfff00000 0x00000100>;
			interrupt-parent = <&hps_0_arm_gic_0>;
			interrupts = <0 154 4>;
			#address-cells = <1>;	/* embeddedsw.dts.params.#address-cells type NUMBER */
			#size-cells = <0>;	/* embeddedsw.dts.params.#size-cells type NUMBER */
			bus-num = <0>;	/* embeddedsw.dts.params.bus-num type NUMBER */
			num-chipselect = <4>;	/* embeddedsw.dts.params.num-chipselect type NUMBER */
			status = "disabled";	/* embeddedsw.dts.params.status type STRING */
		}; //end spi@0xfff00000 (hps_0_spim0)

		hps_0_spim1: spi@0xfff01000 {
			compatible = "snps,dw-spi-mmio-15.1", "snps,dw-spi-mmio", "snps,dw-apb-ssi";
			reg = <0xfff01000 0x00000100>;
			interrupt-parent = <&hps_0_arm_gic_0>;
			interrupts = <0 155 4>;
			#address-cells = <1>;	/* embeddedsw.dts.params.#address-cells type NUMBER */
			#size-cells = <0>;	/* embeddedsw.dts.params.#size-cells type NUMBER */
			bus-num = <0>;	/* embeddedsw.dts.params.bus-num type NUMBER */
			num-chipselect = <4>;	/* embeddedsw.dts.params.num-chipselect type NUMBER */
			status = "okay";	/* embeddedsw.dts.params.status type STRING */
		}; //end spi@0xfff01000 (hps_0_spim1)

		hps_0_qspi: flash@0xff705000 {
			compatible = "cadence,qspi-15.1", "cadence,qspi", "cdns,qspi-nor";
			reg = <0xff705000 0x00000100>,
				<0xffa00000 0x00000100>;
			reg-names = "axi_slave0", "axi_slave1";
			interrupt-parent = <&hps_0_arm_gic_0>;
			interrupts = <0 151 4>;
			bus-num = <2>;	/* embeddedsw.dts.params.bus-num type NUMBER */
			fifo-depth = <128>;	/* embeddedsw.dts.params.fifo-depth type NUMBER */
			num-chipselect = <4>;	/* embeddedsw.dts.params.num-chipselect type NUMBER */
			status = "okay";	/* embeddedsw.dts.params.status type STRING */
			bank-width = <2>;
			device-width = <1>;
			master-ref-clk = <400000000>;	/* appended from boardinfo */
			ext-decoder = <0>;	/* appended from boardinfo */
			#address-cells = <1>;	/* appended from boardinfo */
			#size-cells = <0>;	/* appended from boardinfo */

			flash0: n25q00@0 {
				#address-cells = <1>;	/* appended from boardinfo */
				#size-cells = <1>;	/* appended from boardinfo */
				compatible = "n25q00";	/* appended from boardinfo */
				reg = <0>;	/* appended from boardinfo */
				spi-max-frequency = <100000000>;	/* appended from boardinfo */
				page-size = <256>;	/* appended from boardinfo */
				block-size = <16>;	/* appended from boardinfo */
				m25p,fast-read;	/* appended from boardinfo */
				read-delay = <4>;	/* appended from boardinfo */
				tshsl-ns = <50>;	/* appended from boardinfo */
				tsd2d-ns = <50>;	/* appended from boardinfo */
				tchsh-ns = <4>;	/* appended from boardinfo */
				tslch-ns = <4>;	/* appended from boardinfo */

				part0: partition@0 {
					label = "Flash 0 Raw Data";	/* appended from boardinfo */
					reg = <0x00000000 0x00800000>;	/* appended from boardinfo */
				}; //end partition@0 (part0)

				part1: partition@800000 {
					label = "Flash 1 jffs2 Filesystem";	/* appended from boardinfo */
					reg = <0x00800000 0x00800000>;	/* appended from boardinfo */
				}; //end partition@800000 (part1)
			}; //end n25q00@0 (flash0)
		}; //end flash@0xff705000 (hps_0_qspi)

		hps_0_sdmmc: flash@0xff704000 {
			compatible = "altr,socfpga-dw-mshc";	/* appended from boardinfo */
			reg = <0xff704000 0x00001000>;
			interrupt-parent = <&hps_0_arm_gic_0>;
			interrupts = <0 139 4>;
			fifo-depth = <1024>;	/* embeddedsw.dts.params.fifo-depth type NUMBER */
			num-slots = <1>;	/* embeddedsw.dts.params.num-slots type NUMBER */
			status = "okay";	/* embeddedsw.dts.params.status type STRING */
			bank-width = <2>;
			device-width = <1>;
			clocks = <&l4_mp_clk &sdmmc_clk>;	/* appended from boardinfo */
			clock-names = "biu", "ciu";	/* appended from boardinfo */
			#address-cells = <1>;	/* appended from boardinfo */
			#size-cells = <0>;	/* appended from boardinfo */
			supports-highspeed;	/* appended from boardinfo */
			broken-cd;	/* appended from boardinfo */
			altr,dw-mshc-ciu-div = <3>;	/* appended from boardinfo */
			altr,dw-mshc-sdr-timing = <0 3>;	/* appended from boardinfo */

			slot_0: slot@0 {
				reg = <0>;	/* appended from boardinfo */
				bus-width = <4>;	/* appended from boardinfo */
			}; //end slot@0 (slot_0)
		}; //end flash@0xff704000 (hps_0_sdmmc)

		hps_0_usb0: usb@0xffb00000 {
			compatible = "snps,dwc-otg-15.1", "snps,dwc-otg", "snps,dwc2";
			reg = <0xffb00000 0x00040000>;
			interrupt-parent = <&hps_0_arm_gic_0>;
			interrupts = <0 125 4>;
			clock-names = "otg";	/* embeddedsw.dts.params.clock-names type STRING */
			dev-nperio-tx-fifo-size = <4096>;	/* embeddedsw.dts.params.dev-nperio-tx-fifo-size type NUMBER */
			dev-perio-tx-fifo-size = "<512 512 512 512 512 512 512 512 512 512 512 512 512 512 512>";	/* embeddedsw.dts.params.dev-perio-tx-fifo-size type STRING */
			dev-rx-fifo-size = <512>;	/* embeddedsw.dts.params.dev-rx-fifo-size type NUMBER */
			dev-tx-fifo-size = "<512 512 512 512 512 512 512 512 512 512 512 512 512 512 512>";	/* embeddedsw.dts.params.dev-tx-fifo-size type STRING */
			dma-mask = <268435455>;	/* embeddedsw.dts.params.dma-mask type NUMBER */
			enable-dynamic-fifo = <1>;	/* embeddedsw.dts.params.enable-dynamic-fifo type NUMBER */
			host-nperio-tx-fifo-size = <2560>;	/* embeddedsw.dts.params.host-nperio-tx-fifo-size type NUMBER */
			host-perio-tx-fifo-size = <2560>;	/* embeddedsw.dts.params.host-perio-tx-fifo-size type NUMBER */
			host-rx-fifo-size = <2560>;	/* embeddedsw.dts.params.host-rx-fifo-size type NUMBER */
			phy-names = "usb2-phy";	/* embeddedsw.dts.params.phy-names type STRING */
			status = "disabled";	/* appended from boardinfo */
			ulpi-ddr = <0>;	/* embeddedsw.dts.params.ulpi-ddr type NUMBER */
			voltage-switch = <0>;	/* embeddedsw.dts.params.voltage-switch type NUMBER */
		}; //end usb@0xffb00000 (hps_0_usb0)

		hps_0_usb1: usb@0xffb40000 {
			compatible = "snps,dwc-otg-15.1", "snps,dwc-otg", "snps,dwc2";
			reg = <0xffb40000 0x00040000>;
			interrupt-parent = <&hps_0_arm_gic_0>;
			interrupts = <0 128 4>;
			clock-names = "otg";	/* embeddedsw.dts.params.clock-names type STRING */
			dev-nperio-tx-fifo-size = <4096>;	/* embeddedsw.dts.params.dev-nperio-tx-fifo-size type NUMBER */
			dev-perio-tx-fifo-size = "<512 512 512 512 512 512 512 512 512 512 512 512 512 512 512>";	/* embeddedsw.dts.params.dev-perio-tx-fifo-size type STRING */
			dev-rx-fifo-size = <512>;	/* embeddedsw.dts.params.dev-rx-fifo-size type NUMBER */
			dev-tx-fifo-size = "<512 512 512 512 512 512 512 512 512 512 512 512 512 512 512>";	/* embeddedsw.dts.params.dev-tx-fifo-size type STRING */
			dma-mask = <268435455>;	/* embeddedsw.dts.params.dma-mask type NUMBER */
			enable-dynamic-fifo = <1>;	/* embeddedsw.dts.params.enable-dynamic-fifo type NUMBER */
			host-nperio-tx-fifo-size = <2560>;	/* embeddedsw.dts.params.host-nperio-tx-fifo-size type NUMBER */
			host-perio-tx-fifo-size = <2560>;	/* embeddedsw.dts.params.host-perio-tx-fifo-size type NUMBER */
			host-rx-fifo-size = <2560>;	/* embeddedsw.dts.params.host-rx-fifo-size type NUMBER */
			phy-names = "usb2-phy";	/* embeddedsw.dts.params.phy-names type STRING */
			status = "okay";	/* embeddedsw.dts.params.status type STRING */
			ulpi-ddr = <0>;	/* embeddedsw.dts.params.ulpi-ddr type NUMBER */
			voltage-switch = <0>;	/* embeddedsw.dts.params.voltage-switch type NUMBER */
		}; //end usb@0xffb40000 (hps_0_usb1)

		hps_0_gmac0: ethernet@0xff700000 {
			compatible = "synopsys,dwmac-15.1", "altr,socfpga-stmmac", "snps,dwmac-3.70a", "snps,dwmac";
			reg = <0xff700000 0x00002000>;
			interrupt-parent = <&hps_0_arm_gic_0>;
			interrupts = <0 115 4>;
			clock-names = "stmmaceth";	/* appended from boardinfo */
			interrupt-names = "macirq";	/* embeddedsw.dts.params.interrupt-names type STRING */
			rx-fifo-depth = <4096>;	/* embeddedsw.dts.params.rx-fifo-depth type NUMBER */
			snps,multicast-filter-bins = <256>;	/* embeddedsw.dts.params.snps,multicast-filter-bins type NUMBER */
			snps,perfect-filter-entries = <128>;	/* embeddedsw.dts.params.snps,perfect-filter-entries type NUMBER */
			status = "disabled";	/* appended from boardinfo */
			tx-fifo-depth = <4096>;	/* embeddedsw.dts.params.tx-fifo-depth type NUMBER */
			address-bits = <48>;
			max-frame-size = <1518>;
			local-mac-address = [00 00 00 00 00 00];
			clocks = <&emac0_clk>;	/* appended from boardinfo */
		}; //end ethernet@0xff700000 (hps_0_gmac0)

		hps_0_gmac1: ethernet@0xff702000 {
			compatible = "synopsys,dwmac-15.1", "altr,socfpga-stmmac", "snps,dwmac-3.70a", "snps,dwmac";
			reg = <0xff702000 0x00002000>;
			interrupt-parent = <&hps_0_arm_gic_0>;
			interrupts = <0 120 4>;
			clock-names = "stmmaceth";	/* appended from boardinfo */
			interrupt-names = "macirq";	/* embeddedsw.dts.params.interrupt-names type STRING */
			rx-fifo-depth = <4096>;	/* embeddedsw.dts.params.rx-fifo-depth type NUMBER */
			snps,multicast-filter-bins = <256>;	/* embeddedsw.dts.params.snps,multicast-filter-bins type NUMBER */
			snps,perfect-filter-entries = <128>;	/* embeddedsw.dts.params.snps,perfect-filter-entries type NUMBER */
			status = "okay";	/* embeddedsw.dts.params.status type STRING */
			tx-fifo-depth = <4096>;	/* embeddedsw.dts.params.tx-fifo-depth type NUMBER */
			address-bits = <48>;
			max-frame-size = <1518>;
			local-mac-address = [00 00 00 00 00 00];
			phy-mode = "rgmii";	/* appended from boardinfo */
			clocks = <&emac1_clk>;	/* appended from boardinfo */
			phy-addr = <0xffffffff>;	/* appended from boardinfo */
			micrel-ksz9021rlrn-clk-skew = <0x0000a0e0>;	/* appended from boardinfo */
			micrel-ksz9021rlrn-rx-skew = <0x00000000>;	/* appended from boardinfo */
		}; //end ethernet@0xff702000 (hps_0_gmac1)

		hps_0_dcan0: can@0xffc00000 {
			compatible = "bosch,dcan-15.1", "bosch,d_can";
			reg = <0xffc00000 0x00001000>;
			interrupt-parent = <&hps_0_arm_gic_0>;
			interrupts = <0 131 4 0 132 4>;
			interrupt-names = "interrupt_sender0", "interrupt_sender1";
			status = "disabled";	/* embeddedsw.dts.params.status type STRING */
		}; //end can@0xffc00000 (hps_0_dcan0)

		hps_0_dcan1: can@0xffc01000 {
			compatible = "bosch,dcan-15.1", "bosch,d_can";
			reg = <0xffc01000 0x00001000>;
			interrupt-parent = <&hps_0_arm_gic_0>;
			interrupts = <0 135 4 0 136 4>;
			interrupt-names = "interrupt_sender0", "interrupt_sender1";
			status = "disabled";	/* embeddedsw.dts.params.status type STRING */
		}; //end can@0xffc01000 (hps_0_dcan1)

		hps_0_l3regs: rl3regs@0xff800000 {
			compatible = "altr,l3regs-15.1", "altr,l3regs", "syscon";
			reg = <0xff800000 0x00001000>;
		}; //end rl3regs@0xff800000 (hps_0_l3regs)

		hps_0_sdrctl: sdr-ctl@0xffc25000 {
			compatible = "altr,sdr-ctl-15.1", "altr,sdr-ctl", "syscon";
			reg = <0xffc25000 0x00001000>;
		}; //end sdr-ctl@0xffc25000 (hps_0_sdrctl)

		hps_0_timer: timer@0xfffec600 {
			compatible = "arm,cortex-a9-twd-timer-15.1", "arm,cortex-a9-twd-timer";
			reg = <0xfffec600 0x00000100>;
			interrupt-parent = <&hps_0_arm_gic_0>;
			interrupts = <1 13 3844>;
		}; //end timer@0xfffec600 (hps_0_timer)

		hps_0_scu: scu@0xfffec000 {
			compatible = "arm,corex-a9-scu-15.1", "arm,cortex-a9-scu";
			reg = <0xfffec000 0x00000100>;
		}; //end scu@0xfffec000 (hps_0_scu)

		soc_leds: leds {
			compatible = "gpio-leds";	/* appended from boardinfo */

			led_hps0: hps0 {
				label = "hps_led0";	/* appended from boardinfo */
				gpios = <&hps_0_gpio1 15 1>;	/* appended from boardinfo */
			}; //end hps0 (led_hps0)

			led_hps1: hps1 {
				label = "hps_led1";	/* appended from boardinfo */
				gpios = <&hps_0_gpio1 14 1>;	/* appended from boardinfo */
			}; //end hps1 (led_hps1)

			led_hps2: hps2 {
				label = "hps_led2";	/* appended from boardinfo */
				gpios = <&hps_0_gpio1 13 1>;	/* appended from boardinfo */
			}; //end hps2 (led_hps2)

			led_hps3: hps3 {
				label = "hps_led3";	/* appended from boardinfo */
				gpios = <&hps_0_gpio1 12 1>;	/* appended from boardinfo */
			}; //end hps3 (led_hps3)

			led_fpga0: fpga0 {
				label = "fpga_led0";	/* appended from boardinfo */
				gpios = <&led_pio 0 1>;	/* appended from boardinfo */
			}; //end fpga0 (led_fpga0)

			led_fpga1: fpga1 {
				label = "fpga_led1";	/* appended from boardinfo */
				gpios = <&led_pio 1 1>;	/* appended from boardinfo */
			}; //end fpga1 (led_fpga1)

			led_fpga2: fpga2 {
				label = "fpga_led2";	/* appended from boardinfo */
				gpios = <&led_pio 2 1>;	/* appended from boardinfo */
			}; //end fpga2 (led_fpga2)

			led_fpga3: fpga3 {
				label = "fpga_led3";	/* appended from boardinfo */
				gpios = <&led_pio 3 1>;	/* appended from boardinfo */
			}; //end fpga3 (led_fpga3)
		}; //end leds (soc_leds)

		pmu: pmu0 {
			#address-cells = <1>;	/* appended from boardinfo */
			#size-cells = <1>;	/* appended from boardinfo */
			compatible = "arm,cortex-a9-pmu";	/* appended from boardinfo */
			interrupt-parent = <&hps_0_arm_gic_0>;	/* appended from boardinfo */
			interrupts = <0 176 4 0 177 4>;	/* appended from boardinfo */
			ranges;	/* appended from boardinfo */

			cti0: cti0@ff118000 {
				compatible = "arm,coresight-cti";	/* appended from boardinfo */
				reg = <0xff118000 0x00000100>;	/* appended from boardinfo */
			}; //end cti0@ff118000 (cti0)

			cti1: cti0@ff119000 {
				compatible = "arm,coresight-cti";	/* appended from boardinfo */
				reg = <0xff119000 0x00000100>;	/* appended from boardinfo */
			}; //end cti0@ff119000 (cti1)
		}; //end pmu0 (pmu)

		fpgabridge0: fpgabridge@0 {
			compatible = "altr,socfpga-hps2fpga-bridge";	/* appended from boardinfo */
			label = "hps2fpga";	/* appended from boardinfo */
			clocks = <&l4_main_clk>;	/* appended from boardinfo */
		}; //end fpgabridge@0 (fpgabridge0)

		fpgabridge1: fpgabridge@1 {
			compatible = "altr,socfpga-lwhps2fpga-bridge";	/* appended from boardinfo */
			label = "lwhps2fpga";	/* appended from boardinfo */
			clocks = <&l4_main_clk>;	/* appended from boardinfo */
		}; //end fpgabridge@1 (fpgabridge1)

		fpgabridge2: fpgabridge@2 {
			compatible = "altr,socfpga-fpga2hps-bridge";	/* appended from boardinfo */
			label = "fpga2hps";	/* appended from boardinfo */
			clocks = <&l4_main_clk>;	/* appended from boardinfo */
		}; //end fpgabridge@2 (fpgabridge2)

		l3regs: l3regs@0xff800000 {
			compatible = "altr,l3regs", "syscon";	/* appended from boardinfo */
			reg = <0xff800000 0x00001000>;	/* appended from boardinfo */
		}; //end l3regs@0xff800000 (l3regs)

		sdctrl: sdrctl@0xffc25000 {
			compatible = "altr,sdr-ctl", "syscon";	/* appended from boardinfo */
			reg = <0xffc25000 0x00001000>;	/* appended from boardinfo */
		}; //end sdrctl@0xffc25000 (sdctrl)
	}; //end sopc@0 (sopc0)

	chosen {
		bootargs = "console=ttyS0,115200";
	}; //end chosen

	spidev0: spidev@0 {
		compatible = "spidev";	/* appended from boardinfo */
		reg = <0>;	/* appended from boardinfo */
		spi-max-frequency = <100000000>;	/* appended from boardinfo */
		enable-dma = <1>;	/* appended from boardinfo */
	}; //end spidev@0 (spidev0)

	spidev1: spidev@0 {
		compatible = "spidev";	/* appended from boardinfo */
		reg = <0>;	/* appended from boardinfo */
		spi-max-frequency = <100000000>;	/* appended from boardinfo */
		enable-dma = <1>;	/* appended from boardinfo */
	}; //end spidev@0 (spidev1)
}; //end /
